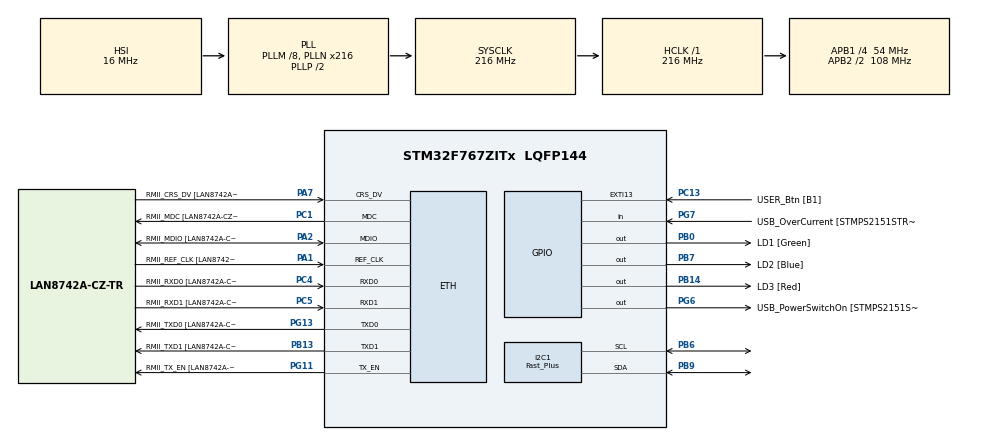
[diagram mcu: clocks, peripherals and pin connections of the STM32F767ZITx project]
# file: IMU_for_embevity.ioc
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CORTEX_M7.CPU_DCache=Disabled
CORTEX_M7.CPU_ICache=Disabled
CORTEX_M7.PREFETCH_ENABLE=0
ETH.MediaInterface=HAL_ETH_RMII_MODE
ETH.RxBuffLen=1536
ETH.RxMode=ETH_RXINTERRUPT_MODE
FREERTOS.INCLUDE_xTaskGetCurrentTaskHandle=1
FREERTOS.Tasks01=defaultTask,24,1024,StartDefaultTask,Default,NULL,Dynamic,NULL,NULL
FREERTOS.configCHECK_FOR_STACK_OVERFLOW=2
FREERTOS.configMINIMAL_STACK_SIZE=256
FREERTOS.configRECORD_STACK_HIGH_ADDRESS=1
FREERTOS.configUSE_MALLOC_FAILED_HOOK=1
FREERTOS.configUSE_NEWLIB_REENTRANT=1
I2C1.I2C_Speed_Mode=I2C_Fast_Plus
I2C1.Timing=0x00200922
LWIP.BSP.number=1
LWIP.CHECKSUM_BY_HARDWARE=1
LWIP.CHECKSUM_CHECK_ICMP=0
LWIP.CHECKSUM_CHECK_UDP=0
LWIP.CHECKSUM_GEN_ICMP=0
LWIP.IP_ADDRESS=192.168.000.234
LWIP.LWIP_BROADCAST_PING=0
LWIP.LWIP_DHCP=0
LWIP.MEM_SIZE=10*1024
LWIP.NETMASK_ADDRESS=255.255.000.000
LWIP.Version=v2.1.2_Cube
LWIP0.BSP.STBoard=false
LWIP0.BSP.api=BSP_COMPONENT_DRIVER
LWIP0.BSP.component=LAN8742
LWIP0.BSP.instance=LAN8742
LWIP0.BSP.name=Driver_PHY
LWIP0.BSP.semaphore=S_LAN8742
LWIP0.BSP.solution=LAN8742
Mcu.Family=STM32F7
Mcu.Name=STM32F767ZITx
Mcu.Package=LQFP144
NVIC.ETH_IRQn=true\:5\:0\:false\:false\:true\:true\:false\:true\:true
NVIC.PriorityGroup=NVIC_PRIORITYGROUP_4
NVIC.TIM1_TRG_COM_TIM11_IRQn=true\:15\:0\:false\:false\:true\:false\:false\:true\:true
NVIC.TimeBase=TIM1_TRG_COM_TIM11_IRQn
NVIC.TimeBaseIP=TIM11
PA1.GPIO_Label=RMII_REF_CLK [LAN8742A-CZ-TR_REFCLK0]
PA1.Mode=RMII
PA1.Signal=ETH_REF_CLK
PA10.GPIO_Label=USB_ID
PA10.Signal=USB_OTG_FS_ID
PA11.GPIO_Label=USB_DM
PA11.Signal=USB_OTG_FS_DM
PA12.GPIO_Label=USB_DP
PA12.Signal=USB_OTG_FS_DP
PA13.GPIO_Label=TMS
PA13.Mode=Trace_Asynchronous_SW
PA13.Signal=SYS_JTMS-SWDIO
PA14.GPIO_Label=TCK
PA14.Mode=Trace_Asynchronous_SW
PA14.Signal=SYS_JTCK-SWCLK
PA2.GPIO_Label=RMII_MDIO [LAN8742A-CZ-TR_MDIO]
PA2.Mode=RMII
PA2.Signal=ETH_MDIO
PA7.GPIO_Label=RMII_CRS_DV [LAN8742A-CZ-TR_CRS_DV]
PA7.Mode=RMII
PA7.Signal=ETH_CRS_DV
PA8.GPIO_Label=USB_SOF [TP1]
PA8.Signal=USB_OTG_FS_SOF
PA9.GPIO_Label=USB_VBUS
PA9.Signal=USB_OTG_FS_VBUS
PB0.GPIO_Label=LD1 [Green]
PB0.Signal=GPIO_Output
PB13.GPIO_Label=RMII_TXD1 [LAN8742A-CZ-TR_TXD1]
PB13.Mode=RMII
PB13.Signal=ETH_TXD1
PB14.GPIO_Label=LD3 [Red]
PB14.Signal=GPIO_Output
PB3.GPIO_Label=SW0
PB3.Mode=Trace_Asynchronous_SW
PB3.Signal=SYS_JTDO-SWO
PB6.Mode=I2C
PB6.Signal=I2C1_SCL
PB7.GPIO_Label=LD2 [Blue]
PB7.Signal=GPIO_Output
PB9.Mode=I2C
PB9.Signal=I2C1_SDA
PC1.GPIO_Label=RMII_MDC [LAN8742A-CZ-TR_MDC]
PC1.Mode=RMII
PC1.Signal=ETH_MDC
PC13.GPIO_Label=USER_Btn [B1]
PC13.Signal=GPXTI13
PC14/OSC32_IN.Signal=RCC_OSC32_IN
PC15/OSC32_OUT.Signal=RCC_OSC32_OUT
PC4.GPIO_Label=RMII_RXD0 [LAN8742A-CZ-TR_RXD0]
PC4.Mode=RMII
PC4.Signal=ETH_RXD0
PC5.GPIO_Label=RMII_RXD1 [LAN8742A-CZ-TR_RXD1]
PC5.Mode=RMII
PC5.Signal=ETH_RXD1
PD8.GPIO_Label=STLK_RX [STM32F103CBT6_PA3]
PD8.Signal=USART3_TX
PD9.GPIO_Label=STLK_TX [STM32F103CBT6_PA2]
PD9.Signal=USART3_RX
PG11.GPIO_Label=RMII_TX_EN [LAN8742A-CZ-TR_TXEN]
PG11.Mode=RMII
PG11.Signal=ETH_TX_EN
PG13.GPIO_Label=RMII_TXD0 [LAN8742A-CZ-TR_TXD0]
PG13.Mode=RMII
PG13.Signal=ETH_TXD0
PG6.GPIO_Label=USB_PowerSwitchOn [STMPS2151STR_EN]
PG6.Signal=GPIO_Output
PG7.GPIO_Label=USB_OverCurrent [STMPS2151STR_FAULT]
PG7.Signal=GPIO_Input
PH0/OSC_IN.GPIO_Label=MCO [STM32F103CBT6_PA8]
PH0/OSC_IN.Signal=RCC_OSC_IN
PH1/OSC_OUT.Signal=RCC_OSC_OUT
ProjectManager.HeapSize=0x200
ProjectManager.StackSize=0x400
ProjectManager.TargetToolchain=STM32CubeIDE
RCC.48MHZClocksFreq_Value=24000000
RCC.AHBFreq_Value=216000000
RCC.APB1CLKDivider=RCC_HCLK_DIV4
RCC.APB1Freq_Value=54000000
RCC.APB1TimFreq_Value=108000000
RCC.APB2CLKDivider=RCC_HCLK_DIV2
RCC.APB2Freq_Value=108000000
RCC.APB2TimFreq_Value=216000000
RCC.CortexFreq_Value=216000000
RCC.HCLKFreq_Value=216000000
RCC.HSE_VALUE=16000000
RCC.HSI_VALUE=16000000
RCC.LSE_VALUE=32768
RCC.PLLM=8
RCC.PLLMUL=RCC_PLL_MUL9
RCC.PLLN=216
RCC.PRESCALERUSB=RCC_USBCLKSOURCE_PLL_DIV1_5
RCC.SYSCLKFreq_VALUE=216000000
RCC.SYSCLKSource=RCC_SYSCLKSOURCE_PLLCLK
RCC.SYSCLKSourceVirtual=RCC_SYSCLKSOURCE_PLLCLK
RCC.USBFreq_Value=216000000
RCC.VCOOutputFreq_Value=432000000
VP_FREERTOS_VS_CMSIS_V2.Mode=CMSIS_V2
VP_LWIP_VS_Enabled.Mode=Enabled
VP_SYS_VS_tim11.Mode=TIM11
board=NUCLEO-F767ZI

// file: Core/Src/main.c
/* USER CODE BEGIN Header */
/**
  ******************************************************************************
  * @file           : main.c
  * @brief          : Main program body
  ******************************************************************************
  * @attention
  *
  * Copyright (c) 2025 STMicroelectronics.
  * All rights reserved.
  *
  * This software is licensed under terms that can be found in the LICENSE file
  * in the root directory of this software component.
  * If no LICENSE file comes with this software, it is provided AS-IS.
  *
  ******************************************************************************
  */
/* USER CODE END Header */
#include "main.h"
#include "cmsis_os.h"
#include "i2c.h"
#include "lwip.h"
#include "gpio.h"

void SystemClock_Config(void);
void MX_FREERTOS_Init(void);

int main(void)
{

  /* MCU Configuration--------------------------------------------------------*/

  /* Reset of all peripherals, Initializes the Flash interface and the Systick. */
  HAL_Init();

  /* Configure the system clock */
  SystemClock_Config();

  /* Initialize all configured peripherals */
  MX_GPIO_Init();
  MX_I2C1_Init();

  /* Init scheduler */
  osKernelInitialize();

  /* Call init function for freertos objects (in cmsis_os2.c) */
  MX_FREERTOS_Init();

  /* Start scheduler */
  osKernelStart();

  /* We should never get here as control is now taken by the scheduler */

  /* Infinite loop */
  while (1)
  {

  }
}

void SystemClock_Config(void)
{
  RCC_OscInitTypeDef RCC_OscInitStruct = {0};
  RCC_ClkInitTypeDef RCC_ClkInitStruct = {0};

  /** Configure the main internal regulator output voltage
  */
  __HAL_RCC_PWR_CLK_ENABLE();
  __HAL_PWR_VOLTAGESCALING_CONFIG(PWR_REGULATOR_VOLTAGE_SCALE1);

  /** Initializes the RCC Oscillators according to the specified parameters
  * in the RCC_OscInitTypeDef structure.
  */
  RCC_OscInitStruct.OscillatorType = RCC_OSCILLATORTYPE_HSI;
  RCC_OscInitStruct.HSIState = RCC_HSI_ON;
  RCC_OscInitStruct.HSICalibrationValue = RCC_HSICALIBRATION_DEFAULT;
  RCC_OscInitStruct.PLL.PLLState = RCC_PLL_ON;
  RCC_OscInitStruct.PLL.PLLSource = RCC_PLLSOURCE_HSI;
  RCC_OscInitStruct.PLL.PLLM = 8;
  RCC_OscInitStruct.PLL.PLLN = 216;
  RCC_OscInitStruct.PLL.PLLP = RCC_PLLP_DIV2;
  RCC_OscInitStruct.PLL.PLLQ = 2;
  RCC_OscInitStruct.PLL.PLLR = 2;
  if (HAL_RCC_OscConfig(&RCC_OscInitStruct) != HAL_OK)
  {
    Error_Handler();
  }

  /** Activate the Over-Drive mode
  */
  if (HAL_PWREx_EnableOverDrive() != HAL_OK)
  {
    Error_Handler();
  }

  /** Initializes the CPU, AHB and APB buses clocks
  */
  RCC_ClkInitStruct.ClockType = RCC_CLOCKTYPE_HCLK|RCC_CLOCKTYPE_SYSCLK
                              |RCC_CLOCKTYPE_PCLK1|RCC_CLOCKTYPE_PCLK2;
  RCC_ClkInitStruct.SYSCLKSource = RCC_SYSCLKSOURCE_PLLCLK;
  RCC_ClkInitStruct.AHBCLKDivider = RCC_SYSCLK_DIV1;
  RCC_ClkInitStruct.APB1CLKDivider = RCC_HCLK_DIV4;
  RCC_ClkInitStruct.APB2CLKDivider = RCC_HCLK_DIV2;

  if (HAL_RCC_ClockConfig(&RCC_ClkInitStruct, FLASH_LATENCY_7) != HAL_OK)
  {
    Error_Handler();
  }
}

void HAL_TIM_PeriodElapsedCallback(TIM_HandleTypeDef *htim)
{
  if (htim->Instance == TIM11) {
    HAL_IncTick();
  }
}

void Error_Handler(void)
{
  __disable_irq();
  while (1)
  {
  }
}

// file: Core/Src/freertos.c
/* USER CODE BEGIN Header */
/**
  ******************************************************************************
  * File Name          : freertos.c
  * Description        : Code for freertos applications
  ******************************************************************************
  * @attention
  *
  * Copyright (c) 2025 STMicroelectronics.
  * All rights reserved.
  *
  * This software is licensed under terms that can be found in the LICENSE file
  * in the root directory of this software component.
  * If no LICENSE file comes with this software, it is provided AS-IS.
  *
  ******************************************************************************
  */
/* USER CODE END Header */

#include "FreeRTOS.h"
#include "task.h"
#include "main.h"
#include "cmsis_os.h"

/* USER CODE BEGIN Includes */

#include "imu_simulator.h"

/* USER CODE END Includes */

/* Definitions for defaultTask */
osThreadId_t defaultTaskHandle;
const osThreadAttr_t defaultTask_attributes = {
  .name = "defaultTask",
  .stack_size = 1024,
  .priority = (osPriority_t) osPriorityNormal,
};

/* USER CODE BEGIN FunctionPrototypes */

extern osThreadId_t imu_simulator_task_handle;
extern osThreadAttr_t imu_simulator_task_attributes;

/* USER CODE END FunctionPrototypes */

void StartDefaultTask(void *argument);

extern void MX_LWIP_Init(void);
void MX_FREERTOS_Init(void); /* (MISRA C 2004 rule 8.1) */

/* Hook prototypes */
void vApplicationStackOverflowHook(xTaskHandle xTask, signed char *pcTaskName);
void vApplicationMallocFailedHook(void);

/* USER CODE BEGIN 4 */
void vApplicationStackOverflowHook(xTaskHandle xTask, signed char *pcTaskName)
{
   /* Run time stack overflow checking is performed if
   configCHECK_FOR_STACK_OVERFLOW is defined to 1 or 2. This hook function is
   called if a stack overflow is detected. */
	__BKPT(1);
	while(1);
}
/* USER CODE END 4 */

/* USER CODE BEGIN 5 */
void vApplicationMallocFailedHook(void)
{
   /* vApplicationMallocFailedHook() will only be called if
   configUSE_MALLOC_FAILED_HOOK is set to 1 in FreeRTOSConfig.h. It is a hook
   function that will get called if a call to pvPortMalloc() fails.
   pvPortMalloc() is called internally by the kernel whenever a task, queue,
   timer or semaphore is created. It is also called by various parts of the
   demo application. If heap_1.c or heap_2.c are used, then the size of the
   heap available to pvPortMalloc() is defined by configTOTAL_HEAP_SIZE in
   FreeRTOSConfig.h, and the xPortGetFreeHeapSize() API function can be used
   to query the size of free heap space that remains (although it does not
   provide information on how the remaining heap might be fragmented). */
	__BKPT(1);
	while(1);
}
/* USER CODE END 5 */

void MX_FREERTOS_Init(void) {

  /* Create the thread(s) */
  /* creation of defaultTask */
  defaultTaskHandle = osThreadNew(StartDefaultTask, NULL, &defaultTask_attributes);

  /* USER CODE BEGIN RTOS_THREADS */
  /* add threads, ... */
  imu_simulator_task_handle = osThreadNew(imu_simulator_task, NULL, &imu_simulator_task_attributes);
  /* USER CODE END RTOS_THREADS */

}

void StartDefaultTask(void *argument)
{
  /* init code for LWIP */
  MX_LWIP_Init();
  /* USER CODE BEGIN StartDefaultTask */
  /* Infinite loop */
  for(;;)
  {
	HAL_GPIO_TogglePin(LD1_GPIO_Port, LD1_Pin);
    osDelay(500);
  }
  /* USER CODE END StartDefaultTask */
}
